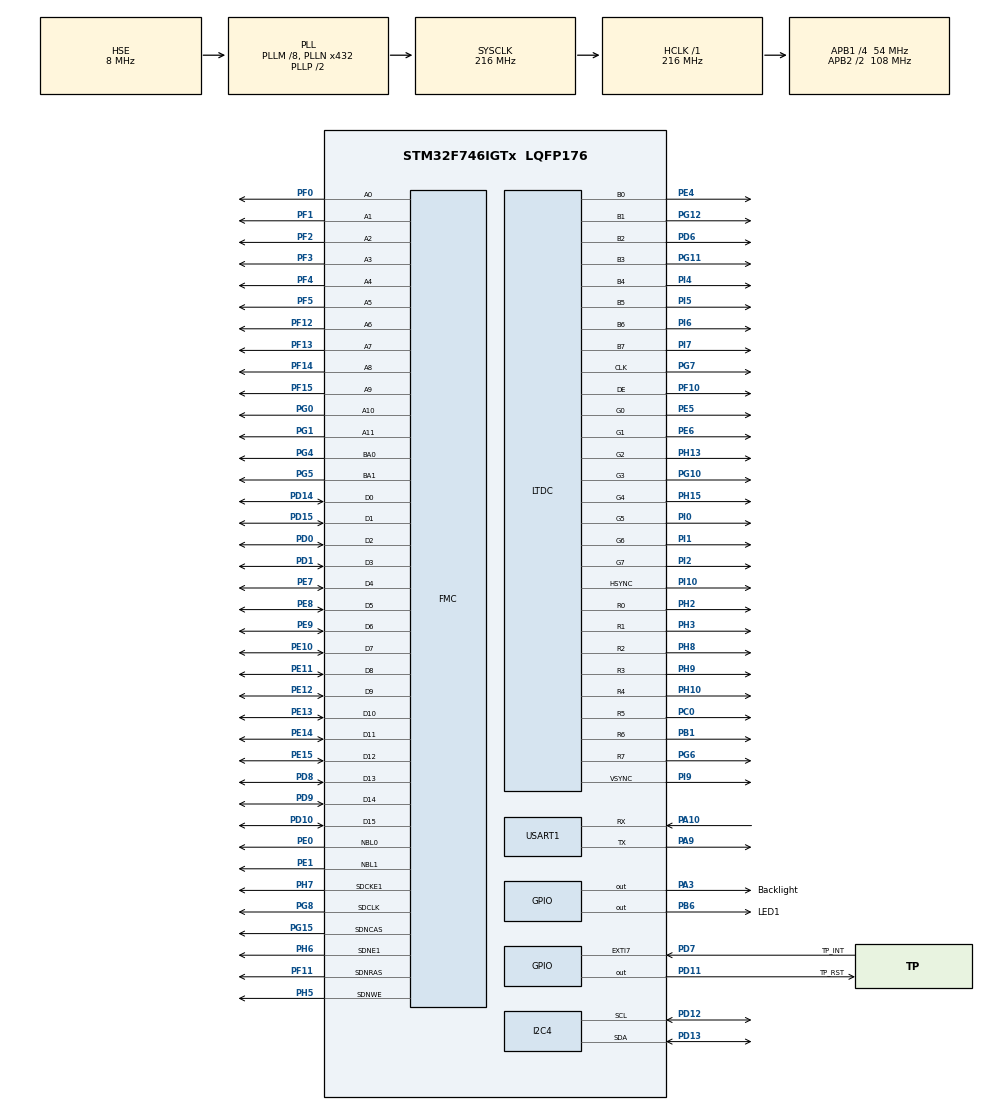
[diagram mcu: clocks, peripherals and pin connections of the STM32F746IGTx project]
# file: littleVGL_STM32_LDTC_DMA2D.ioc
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CORTEX_M7.CPU_DCache=Enabled
CORTEX_M7.CPU_ICache=Enabled
DMA2D.ColorMode=DMA2D_OUTPUT_RGB565
DMA2D.Mode=DMA2D_M2M
Dma.MEMTOMEM.0.Direction=DMA_MEMORY_TO_MEMORY
Dma.MEMTOMEM.0.FIFOMode=DMA_FIFOMODE_ENABLE
Dma.MEMTOMEM.0.FIFOThreshold=DMA_FIFO_THRESHOLD_1QUARTERFULL
Dma.MEMTOMEM.0.Instance=DMA2_Stream0
Dma.MEMTOMEM.0.MemBurst=DMA_MBURST_SINGLE
Dma.MEMTOMEM.0.MemDataAlignment=DMA_MDATAALIGN_HALFWORD
Dma.MEMTOMEM.0.MemInc=DMA_MINC_ENABLE
Dma.MEMTOMEM.0.Mode=DMA_NORMAL
Dma.MEMTOMEM.0.PeriphBurst=DMA_PBURST_SINGLE
Dma.MEMTOMEM.0.PeriphDataAlignment=DMA_PDATAALIGN_HALFWORD
Dma.MEMTOMEM.0.PeriphInc=DMA_PINC_ENABLE
Dma.MEMTOMEM.0.Priority=DMA_PRIORITY_HIGH
Dma.Request0=MEMTOMEM
FMC.CASLatency1=FMC_SDRAM_CAS_LATENCY_2
FMC.ExitSelfRefreshDelay1=5
FMC.LoadToActiveDelay1=2
FMC.RCDDelay1=3
FMC.RPDelay1=2
FMC.ReadBurst1=FMC_SDRAM_RBURST_DISABLE
FMC.ReadPipeDelay1=FMC_SDRAM_RPIPE_DELAY_0
FMC.RowCycleDelay1=7
FMC.RowCycleDelay2=7
FMC.SDClockPeriod1=FMC_SDRAM_CLOCK_PERIOD_2
FMC.SelfRefreshTime1=5
FMC.WriteRecoveryTime1=4
I2C4.I2C_Fall_Time=100
I2C4.I2C_Rise_Time=700
I2C4.Timing=0x30C03444
LTDC.ActiveH=600
LTDC.ActiveW=1024
LTDC.Alpha_L0=0xFF
LTDC.BlendingFactor1_L0=LTDC_BLENDING_FACTOR1_PAxCA
LTDC.BlendingFactor1_L1=LTDC_BLENDING_FACTOR1_PAxCA
LTDC.BlendingFactor2_L0=LTDC_BLENDING_FACTOR2_PAxCA
LTDC.BlendingFactor2_L1=LTDC_BLENDING_FACTOR2_PAxCA
LTDC.FBStartAdress_L0=0xD0200000
LTDC.FBStartAdress_L1=0xD0200000
LTDC.HBP=200
LTDC.HFP=300
LTDC.HSync=100
LTDC.ImageHeight_L0=600
LTDC.ImageHeight_L1=600
LTDC.ImageWidth_L0=1024
LTDC.ImageWidth_L1=1024
LTDC.Layers=0
LTDC.PixelFormat_L0=LTDC_PIXEL_FORMAT_RGB565
LTDC.PixelFormat_L1=LTDC_PIXEL_FORMAT_RGB565
LTDC.VBP=40
LTDC.VFP=24
LTDC.VSync=3
LTDC.WindowX0_L1=0
LTDC.WindowX1_L0=1024
LTDC.WindowX1_L1=1024
LTDC.WindowY0_L1=300
LTDC.WindowY1_L0=600
LTDC.WindowY1_L1=600
Mcu.Family=STM32F7
Mcu.Name=STM32F746IGTx
Mcu.Package=LQFP176
NVIC.DMA2D_IRQn=true\:0\:0\:false\:false\:true\:true\:true
NVIC.DMA2_Stream0_IRQn=true\:0\:0\:false\:false\:true\:true\:true
NVIC.EXTI9_5_IRQn=true\:0\:0\:false\:false\:true\:true\:true
NVIC.FMC_IRQn=true\:0\:0\:false\:false\:true\:true\:true
NVIC.LTDC_IRQn=true\:0\:0\:false\:false\:true\:true\:true
NVIC.PriorityGroup=NVIC_PRIORITYGROUP_4
NVIC.TIM2_IRQn=true\:0\:0\:false\:false\:true\:true\:true
PA10.Mode=Asynchronous
PA10.Signal=USART1_RX
PA3.GPIO_Label=Backlight
PA3.Signal=GPIO_Output
PA9.Mode=Asynchronous
PA9.Signal=USART1_TX
PB1.GPIO_Speed=GPIO_SPEED_FREQ_HIGH
PB1.Mode=RGB888
PB1.Signal=LTDC_R6
PB6.GPIO_Label=LED1
PB6.Signal=GPIO_Output
PC0.GPIO_Speed=GPIO_SPEED_FREQ_HIGH
PC0.Mode=RGB888
PC0.Signal=LTDC_R5
PC14/OSC32_IN.Mode=LSE-External-Oscillator
PC14/OSC32_IN.Signal=RCC_OSC32_IN
PC15/OSC32_OUT.Mode=LSE-External-Oscillator
PC15/OSC32_OUT.Signal=RCC_OSC32_OUT
PD0.Signal=FMC_D2_DA2
PD1.Signal=FMC_D3_DA3
PD10.Signal=FMC_D15_DA15
PD11.GPIO_Label=TP_RST
PD11.Signal=GPIO_Output
PD12.Mode=I2C
PD12.Signal=I2C4_SCL
PD13.Mode=I2C
PD13.Signal=I2C4_SDA
PD14.Signal=FMC_D0_DA0
PD15.Signal=FMC_D1_DA1
PD6.GPIO_Speed=GPIO_SPEED_FREQ_HIGH
PD6.Mode=RGB888
PD6.Signal=LTDC_B2
PD7.GPIO_Label=TP_INT
PD7.Signal=GPXTI7
PD8.Signal=FMC_D13_DA13
PD9.Signal=FMC_D14_DA14
PE0.Signal=FMC_NBL0
PE1.Signal=FMC_NBL1
PE10.Signal=FMC_D7_DA7
PE11.Signal=FMC_D8_DA8
PE12.Signal=FMC_D9_DA9
PE13.Signal=FMC_D10_DA10
PE14.Signal=FMC_D11_DA11
PE15.Signal=FMC_D12_DA12
PE4.GPIO_Speed=GPIO_SPEED_FREQ_HIGH
PE4.Mode=RGB888
PE4.Signal=LTDC_B0
PE5.GPIO_Speed=GPIO_SPEED_FREQ_HIGH
PE5.Mode=RGB888
PE5.Signal=LTDC_G0
PE6.GPIO_Speed=GPIO_SPEED_FREQ_HIGH
PE6.Mode=RGB888
PE6.Signal=LTDC_G1
PE7.Signal=FMC_D4_DA4
PE8.Signal=FMC_D5_DA5
PE9.Signal=FMC_D6_DA6
PF0.Signal=FMC_A0
PF1.Signal=FMC_A1
PF10.GPIO_Speed=GPIO_SPEED_FREQ_HIGH
PF10.Mode=RGB888
PF10.Signal=LTDC_DE
PF11.Signal=FMC_SDNRAS
PF12.Signal=FMC_A6
PF13.Signal=FMC_A7
PF14.Signal=FMC_A8
PF15.Signal=FMC_A9
PF2.Signal=FMC_A2
PF3.Signal=FMC_A3
PF4.Signal=FMC_A4
PF5.Signal=FMC_A5
PG0.Signal=FMC_A10
PG1.Signal=FMC_A11
PG10.GPIO_Speed=GPIO_SPEED_FREQ_HIGH
PG10.Mode=RGB888
PG10.Signal=LTDC_G3
PG11.GPIO_Speed=GPIO_SPEED_FREQ_HIGH
PG11.Mode=RGB888
PG11.Signal=LTDC_B3
PG12.GPIO_Speed=GPIO_SPEED_FREQ_HIGH
PG12.Mode=RGB888
PG12.Signal=LTDC_B1
PG15.Signal=FMC_SDNCAS
PG4.Signal=FMC_A14_BA0
PG5.Signal=FMC_A15_BA1
PG6.GPIO_Speed=GPIO_SPEED_FREQ_HIGH
PG6.Mode=RGB888
PG6.Signal=LTDC_R7
PG7.GPIO_Speed=GPIO_SPEED_FREQ_HIGH
PG7.Mode=RGB888
PG7.Signal=LTDC_CLK
PG8.Signal=FMC_SDCLK
PH0/OSC_IN.Mode=HSE-External-Oscillator
PH0/OSC_IN.Signal=RCC_OSC_IN
PH1/OSC_OUT.Mode=HSE-External-Oscillator
PH1/OSC_OUT.Signal=RCC_OSC_OUT
PH10.GPIO_Speed=GPIO_SPEED_FREQ_HIGH
PH10.Mode=RGB888
PH10.Signal=LTDC_R4
PH13.GPIO_Speed=GPIO_SPEED_FREQ_HIGH
PH13.Mode=RGB888
PH13.Signal=LTDC_G2
PH15.GPIO_Speed=GPIO_SPEED_FREQ_HIGH
PH15.Mode=RGB888
PH15.Signal=LTDC_G4
PH2.GPIO_Speed=GPIO_SPEED_FREQ_HIGH
PH2.Mode=RGB888
PH2.Signal=LTDC_R0
PH3.GPIO_Speed=GPIO_SPEED_FREQ_HIGH
PH3.Mode=RGB888
PH3.Signal=LTDC_R1
PH5.Signal=FMC_SDNWE
PH6.Mode=SdramChipSelect2_1
PH6.Signal=FMC_SDNE1
PH7.Mode=SdramChipSelect2_1
PH7.Signal=FMC_SDCKE1
PH8.GPIO_Speed=GPIO_SPEED_FREQ_HIGH
PH8.Mode=RGB888
PH8.Signal=LTDC_R2
PH9.GPIO_Speed=GPIO_SPEED_FREQ_HIGH
PH9.Mode=RGB888
PH9.Signal=LTDC_R3
PI0.GPIO_Speed=GPIO_SPEED_FREQ_HIGH
PI0.Mode=RGB888
PI0.Signal=LTDC_G5
PI1.GPIO_Speed=GPIO_SPEED_FREQ_HIGH
PI1.Mode=RGB888
PI1.Signal=LTDC_G6
PI10.GPIO_Speed=GPIO_SPEED_FREQ_HIGH
PI10.Mode=RGB888
PI10.Signal=LTDC_HSYNC
PI2.GPIO_Speed=GPIO_SPEED_FREQ_HIGH
PI2.Mode=RGB888
PI2.Signal=LTDC_G7
PI4.GPIO_Speed=GPIO_SPEED_FREQ_HIGH
PI4.Mode=RGB888
PI4.Signal=LTDC_B4
PI5.GPIO_Speed=GPIO_SPEED_FREQ_HIGH
PI5.Mode=RGB888
PI5.Signal=LTDC_B5
PI6.GPIO_Speed=GPIO_SPEED_FREQ_HIGH
PI6.Mode=RGB888
PI6.Signal=LTDC_B6
PI7.GPIO_Speed=GPIO_SPEED_FREQ_HIGH
PI7.Mode=RGB888
PI7.Signal=LTDC_B7
PI9.GPIO_Speed=GPIO_SPEED_FREQ_HIGH
PI9.Mode=RGB888
PI9.Signal=LTDC_VSYNC
ProjectManager.HeapSize=0x1000
ProjectManager.StackSize=0x800
ProjectManager.TargetToolchain=MDK-ARM V5
RCC.AHBFreq_Value=216000000
RCC.APB1CLKDivider=RCC_HCLK_DIV4
RCC.APB1Freq_Value=54000000
RCC.APB1TimFreq_Value=108000000
RCC.APB2CLKDivider=RCC_HCLK_DIV2
RCC.APB2Freq_Value=108000000
RCC.APB2TimFreq_Value=216000000
RCC.CortexFreq_Value=216000000
RCC.HCLKFreq_Value=216000000
RCC.HSE_VALUE=8000000
RCC.HSI_VALUE=16000000
RCC.PLLM=8
RCC.PLLN=432
RCC.PLLSAIN=432
RCC.PLLSAIR=3
RCC.PLLSourceVirtual=RCC_PLLSOURCE_HSE
RCC.SYSCLKFreq_VALUE=216000000
RCC.SYSCLKSource=RCC_SYSCLKSOURCE_PLLCLK
RCC.USBFreq_Value=216000000
RCC.VCOOutputFreq_Value=432000000
SH.FMC_A0.0=FMC_A0,12b-sda1
SH.FMC_A1.0=FMC_A1,12b-sda1
SH.FMC_A10.0=FMC_A10,12b-sda1
SH.FMC_A11.0=FMC_A11,12b-sda1
SH.FMC_A14_BA0.0=FMC_BA0,FourSdramBanks1
SH.FMC_A15_BA1.0=FMC_BA1,FourSdramBanks1
SH.FMC_A2.0=FMC_A2,12b-sda1
SH.FMC_A3.0=FMC_A3,12b-sda1
SH.FMC_A4.0=FMC_A4,12b-sda1
SH.FMC_A5.0=FMC_A5,12b-sda1
SH.FMC_A6.0=FMC_A6,12b-sda1
SH.FMC_A7.0=FMC_A7,12b-sda1
SH.FMC_A8.0=FMC_A8,12b-sda1
SH.FMC_A9.0=FMC_A9,12b-sda1
SH.FMC_D0_DA0.0=FMC_D0,sd-16b-d1
SH.FMC_D10_DA10.0=FMC_D10,sd-16b-d1
SH.FMC_D11_DA11.0=FMC_D11,sd-16b-d1
SH.FMC_D12_DA12.0=FMC_D12,sd-16b-d1
SH.FMC_D13_DA13.0=FMC_D13,sd-16b-d1
SH.FMC_D14_DA14.0=FMC_D14,sd-16b-d1
SH.FMC_D15_DA15.0=FMC_D15,sd-16b-d1
SH.FMC_D1_DA1.0=FMC_D1,sd-16b-d1
SH.FMC_D2_DA2.0=FMC_D2,sd-16b-d1
SH.FMC_D3_DA3.0=FMC_D3,sd-16b-d1
SH.FMC_D4_DA4.0=FMC_D4,sd-16b-d1
SH.FMC_D5_DA5.0=FMC_D5,sd-16b-d1
SH.FMC_D6_DA6.0=FMC_D6,sd-16b-d1
SH.FMC_D7_DA7.0=FMC_D7,sd-16b-d1
SH.FMC_D8_DA8.0=FMC_D8,sd-16b-d1
SH.FMC_D9_DA9.0=FMC_D9,sd-16b-d1
SH.FMC_NBL0.0=FMC_NBL0,Sd2ByteEnable1
SH.FMC_NBL1.0=FMC_NBL1,Sd2ByteEnable1
SH.FMC_SDCLK.0=FMC_SDCLK,12b-sda1
SH.FMC_SDNCAS.0=FMC_SDNCAS,12b-sda1
SH.FMC_SDNRAS.0=FMC_SDNRAS,12b-sda1
SH.FMC_SDNWE.0=FMC_SDNWE,12b-sda1
TIM2.Period=10000-1
TIM2.Prescaler=10800-1
USART1.VirtualMode-Asynchronous=VM_ASYNC
VP_DMA2D_VS_DMA2D.Mode=DMA2D_Activate
VP_TIM2_VS_ClockSourceINT.Mode=Internal
board=custom

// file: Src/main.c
/* USER CODE BEGIN Header */
/**
  ******************************************************************************
  * @file           : main.c
  * @brief          : Main program body
  ******************************************************************************
  * @attention
  *
  * <h2><center>&copy; Copyright (c) 2020 STMicroelectronics.
  * All rights reserved.</center></h2>
  *
  * This software component is licensed by ST under BSD 3-Clause license,
  * the "License"; You may not use this file except in compliance with the
  * License. You may obtain a copy of the License at:
  *                        opensource.org/licenses/BSD-3-Clause
  *
  ******************************************************************************
  */
/* USER CODE END Header */

#include "main.h"
#include "dma.h"
#include "dma2d.h"
#include "i2c.h"
#include "ltdc.h"
#include "tim.h"
#include "usart.h"
#include "gpio.h"
#include "fmc.h"

/* USER CODE BEGIN Includes */
#include <stdio.h>
#include "stm32746i_lcd.h"
#include "stm32746i_sdram.h"
#include "../lvgl/lvgl.h"
#include "../lv_conf.h"
#include "../lv_ex_conf.h"
#include "../porting/lv_port_disp.h"
#include "../porting/lv_port_indev.h"
//#include "../lv_examples/lv_apps/demo/demo.h"
#include "test.h"
/* USER CODE END Includes */

void SystemClock_Config(void);

int main(void)
{

  /* Enable I-Cache---------------------------------------------------------*/
  SCB_EnableICache();

  /* Enable D-Cache---------------------------------------------------------*/
  SCB_EnableDCache();

  /* MCU Configuration--------------------------------------------------------*/

  /* Reset of all peripherals, Initializes the Flash interface and the Systick. */
  HAL_Init();

  /* Configure the system clock */
  SystemClock_Config();

  /* Initialize all configured peripherals */
  MX_GPIO_Init();
  MX_DMA_Init();
  MX_DMA2D_Init();
  MX_FMC_Init();
  MX_I2C4_Init();
  MX_LTDC_Init();
  MX_TIM2_Init();
  MX_USART1_UART_Init();
  /* USER CODE BEGIN 2 */
	HAL_TIM_Base_Start_IT(&htim2);

	lv_init();
	lv_port_disp_init();
	lv_port_indev_init();

	demo_test();

  /* USER CODE END 2 */

  /* Infinite loop */
  while (1)
  {

    /* USER CODE BEGIN 3 */
		lv_task_handler();
		HAL_Delay(5);
  }
  /* USER CODE END 3 */
}

void SystemClock_Config(void)
{
  RCC_OscInitTypeDef RCC_OscInitStruct = {0};
  RCC_ClkInitTypeDef RCC_ClkInitStruct = {0};
  RCC_PeriphCLKInitTypeDef PeriphClkInitStruct = {0};

  /** Configure LSE Drive Capability
  */
  HAL_PWR_EnableBkUpAccess();
  /** Configure the main internal regulator output voltage
  */
  __HAL_RCC_PWR_CLK_ENABLE();
  __HAL_PWR_VOLTAGESCALING_CONFIG(PWR_REGULATOR_VOLTAGE_SCALE1);
  /** Initializes the CPU, AHB and APB busses clocks
  */
  RCC_OscInitStruct.OscillatorType = RCC_OSCILLATORTYPE_HSE;
  RCC_OscInitStruct.HSEState = RCC_HSE_ON;
  RCC_OscInitStruct.PLL.PLLState = RCC_PLL_ON;
  RCC_OscInitStruct.PLL.PLLSource = RCC_PLLSOURCE_HSE;
  RCC_OscInitStruct.PLL.PLLM = 8;
  RCC_OscInitStruct.PLL.PLLN = 432;
  RCC_OscInitStruct.PLL.PLLP = RCC_PLLP_DIV2;
  RCC_OscInitStruct.PLL.PLLQ = 2;
  if (HAL_RCC_OscConfig(&RCC_OscInitStruct) != HAL_OK)
  {
    Error_Handler();
  }
  /** Activate the Over-Drive mode
  */
  if (HAL_PWREx_EnableOverDrive() != HAL_OK)
  {
    Error_Handler();
  }
  /** Initializes the CPU, AHB and APB busses clocks
  */
  RCC_ClkInitStruct.ClockType = RCC_CLOCKTYPE_HCLK|RCC_CLOCKTYPE_SYSCLK
                              |RCC_CLOCKTYPE_PCLK1|RCC_CLOCKTYPE_PCLK2;
  RCC_ClkInitStruct.SYSCLKSource = RCC_SYSCLKSOURCE_PLLCLK;
  RCC_ClkInitStruct.AHBCLKDivider = RCC_SYSCLK_DIV1;
  RCC_ClkInitStruct.APB1CLKDivider = RCC_HCLK_DIV4;
  RCC_ClkInitStruct.APB2CLKDivider = RCC_HCLK_DIV2;

  if (HAL_RCC_ClockConfig(&RCC_ClkInitStruct, FLASH_LATENCY_7) != HAL_OK)
  {
    Error_Handler();
  }
  PeriphClkInitStruct.PeriphClockSelection = RCC_PERIPHCLK_LTDC|RCC_PERIPHCLK_USART1
                              |RCC_PERIPHCLK_I2C4;
  PeriphClkInitStruct.PLLSAI.PLLSAIN = 432;
  PeriphClkInitStruct.PLLSAI.PLLSAIR = 3;
  PeriphClkInitStruct.PLLSAI.PLLSAIQ = 2;
  PeriphClkInitStruct.PLLSAI.PLLSAIP = RCC_PLLSAIP_DIV2;
  PeriphClkInitStruct.PLLSAIDivQ = 1;
  PeriphClkInitStruct.PLLSAIDivR = RCC_PLLSAIDIVR_2;
  PeriphClkInitStruct.Usart1ClockSelection = RCC_USART1CLKSOURCE_PCLK2;
  PeriphClkInitStruct.I2c4ClockSelection = RCC_I2C4CLKSOURCE_PCLK1;
  if (HAL_RCCEx_PeriphCLKConfig(&PeriphClkInitStruct) != HAL_OK)
  {
    Error_Handler();
  }
}

void Error_Handler(void)
{
}

/************************ (C) COPYRIGHT STMicroelectronics *****END OF FILE****/
